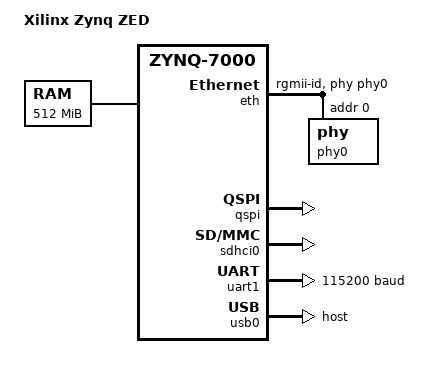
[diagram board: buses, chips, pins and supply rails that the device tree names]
/*
 * CAUTION: This file is automatically generated by Xilinx.
 * Version:  
 * Today is: Thu Nov 17 16:30:03 2016
*/


/dts-v1/;
/include/ "zynq-7000.dtsi"
/include/ "pl.dtsi"

/ {
	model = "Xilinx Zynq ZED";
	cpus {
		cpu@0 {
			operating-points = <666666 1000000 333333 1000000>;
		};
	};
	chosen {
		bootargs = "console=ttyPS0,115200 root=/dev/mmcblk0p2 rw earlyprintk rootfstype=ext4 rootwait";
		linux,stdout-path = "/amba@0/uart@E0001000";
	};
	aliases {
		ethernet0 = &eth;
		serial0 = &uart1;
	};
	memory {
		device_type = "memory";
		reg = <0x0 0x20000000>;
	};
};

&eth {
	phy-handle = <&phy0>;
	phy-mode = "rgmii-id";

	phy0: phy@0 {
		device_type = "ethernet-phy";
		reg = <0x0>;
		marvell,reg-init=<3 16 0xff00 0x1e 3 17 0xfff0 0x0a>;
	};
};

&gpio0 {
	emio-gpio-width = <64>;
	gpio-mask-high = <0x0>;
	gpio-mask-low = <0x5600>;
};
&intc {
	num_cpus = <2>;
	num_interrupts = <96>;
};
&qspi {
	is-dual = <0>;
	num-cs = <1>;
	status = "okay";
};
&sdhci0 {
	status = "okay";
	xlnx,has-cd = <0x1>;
	xlnx,has-power = <0x0>;
	xlnx,has-wp = <0x1>;
};
&uart1 {
	current-speed = <115200>;
	device_type = "serial";
	port-number = <0>;
	status = "okay";
};
&usb0 {
	dr_mode = "host";
	phy_type = "ulpi";
	status = "okay";
};
&clkc {
	fclk-enable = <0x1>;
	ps-clk-frequency = <33333333>;
};
